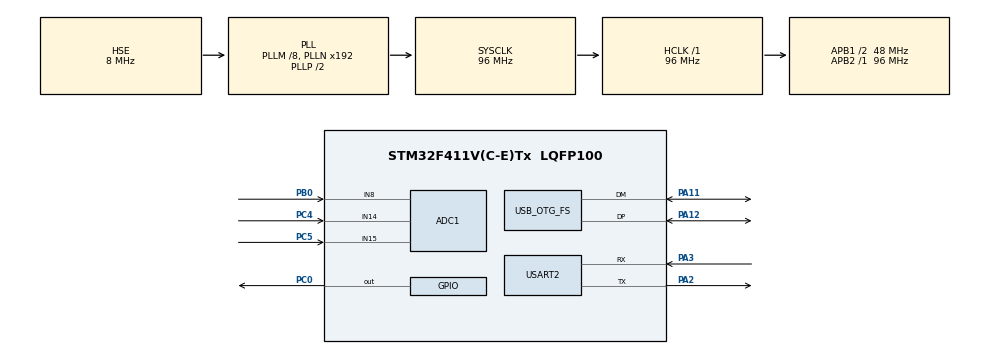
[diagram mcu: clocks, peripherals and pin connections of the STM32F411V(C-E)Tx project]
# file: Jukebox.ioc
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ADC1.Channel-0\#ChannelRegularConversion=ADC_CHANNEL_14
ADC1.Channel-1\#ChannelRegularConversion=ADC_CHANNEL_15
ADC1.Channel-2\#ChannelRegularConversion=ADC_CHANNEL_8
ADC1.ContinuousConvMode=DISABLE
ADC1.DiscontinuousConvMode=ENABLE
ADC1.NbrOfConversion=3
ADC1.NbrOfConversionFlag=1
ADC1.Rank-0\#ChannelRegularConversion=1
ADC1.Rank-1\#ChannelRegularConversion=2
ADC1.Rank-2\#ChannelRegularConversion=3
ADC1.SamplingTime-0\#ChannelRegularConversion=ADC_SAMPLETIME_3CYCLES
ADC1.SamplingTime-1\#ChannelRegularConversion=ADC_SAMPLETIME_3CYCLES
ADC1.SamplingTime-2\#ChannelRegularConversion=ADC_SAMPLETIME_3CYCLES
ADC1.ScanConvMode=ENABLE
ADC1.master=1
Dma.ADC1.0.Direction=DMA_PERIPH_TO_MEMORY
Dma.ADC1.0.FIFOMode=DMA_FIFOMODE_DISABLE
Dma.ADC1.0.Instance=DMA2_Stream0
Dma.ADC1.0.MemDataAlignment=DMA_MDATAALIGN_HALFWORD
Dma.ADC1.0.MemInc=DMA_MINC_ENABLE
Dma.ADC1.0.Mode=DMA_NORMAL
Dma.ADC1.0.PeriphDataAlignment=DMA_PDATAALIGN_HALFWORD
Dma.ADC1.0.PeriphInc=DMA_PINC_DISABLE
Dma.ADC1.0.Priority=DMA_PRIORITY_LOW
Dma.Request0=ADC1
FATFS._FS_EXFAT=1
FATFS._USE_LFN=2
FREERTOS.HEAP_NUMBER=3
FREERTOS.Tasks01=defaultTask,24,128,StartDefaultTask,Default,NULL
Mcu.Family=STM32F4
Mcu.Name=STM32F411V(C-E)Tx
Mcu.Package=LQFP100
NVIC.ADC_IRQn=true\:5\:0\:false\:false\:true\:true\:true\:true
NVIC.DMA2_Stream0_IRQn=true\:5\:0\:false\:false\:true\:true\:false\:true
NVIC.OTG_FS_IRQn=true\:5\:0\:false\:false\:true\:true\:false\:true
NVIC.PriorityGroup=NVIC_PRIORITYGROUP_4
NVIC.TIM1_UP_TIM10_IRQn=true\:0\:0\:false\:false\:true\:false\:false\:true
NVIC.TimeBase=TIM1_UP_TIM10_IRQn
NVIC.TimeBaseIP=TIM1
NVIC.USART2_IRQn=true\:5\:0\:false\:false\:true\:true\:true\:true
PA11.Mode=Host_Only
PA11.Signal=USB_OTG_FS_DM
PA12.Mode=Host_Only
PA12.Signal=USB_OTG_FS_DP
PA2.Mode=Asynchronous
PA2.Signal=USART2_TX
PA3.Mode=Asynchronous
PA3.Signal=USART2_RX
PB0.Signal=ADCx_IN8
PC0.Signal=GPIO_Output
PC4.Signal=ADCx_IN14
PC5.Signal=ADCx_IN15
PH0\ -\ OSC_IN.Mode=HSE-External-Oscillator
PH0\ -\ OSC_IN.Signal=RCC_OSC_IN
PH1\ -\ OSC_OUT.Mode=HSE-External-Oscillator
PH1\ -\ OSC_OUT.Signal=RCC_OSC_OUT
ProjectManager.HeapSize=0x200
ProjectManager.StackSize=0x400
ProjectManager.TargetToolchain=STM32CubeIDE
RCC.48MHZClocksFreq_Value=48000000
RCC.AHBFreq_Value=96000000
RCC.APB1CLKDivider=RCC_HCLK_DIV2
RCC.APB1Freq_Value=48000000
RCC.APB1TimFreq_Value=96000000
RCC.APB2Freq_Value=96000000
RCC.APB2TimFreq_Value=96000000
RCC.CortexFreq_Value=96000000
RCC.HCLKFreq_Value=96000000
RCC.HSE_VALUE=8000000
RCC.HSI_VALUE=16000000
RCC.LSE_VALUE=32768
RCC.PLLM=8
RCC.SYSCLKFreq_VALUE=96000000
RCC.SYSCLKSource=RCC_SYSCLKSOURCE_PLLCLK
RCC.VCOOutputFreq_Value=192000000
SH.ADCx_IN14.0=ADC1_IN14,IN14
SH.ADCx_IN15.0=ADC1_IN15,IN15
SH.ADCx_IN8.0=ADC1_IN8,IN8
USART2.VirtualMode=VM_ASYNC
USB_HOST.BSP.number=1
USB_HOST.USBH_DEBUG_LEVEL=0
USB_HOST.USBH_HandleTypeDef=hUsbHostFS
USB_HOST.USBH_PROCESS_PRIO=osPriorityNormal
USB_HOST.USBH_PROCESS_STACK_SIZE=2048
USB_HOST.VirtualModeFS=Msc
USB_HOST0.BSP.STBoard=false
USB_HOST0.BSP.api=Unknown
USB_HOST0.BSP.i2caddr=0
USB_HOST0.BSP.instance=PC0
USB_HOST0.BSP.ip=GPIO
USB_HOST0.BSP.mode=Output
USB_HOST0.BSP.name=Drive_VBUS_FS
USB_HOST0.BSP.solution=PC0
USB_OTG_FS.VirtualMode=Host_Only
USB_OTG_FS.phy_itface=HCD_PHY_EMBEDDED
VP_CRC_VS_CRC.Mode=CRC_Activate
VP_FATFS_VS_USB.Mode=USB
VP_FREERTOS_VS_CMSIS_V2.Mode=CMSIS_V2
VP_SYS_VS_tim1.Mode=TIM1
VP_USB_HOST_VS_USB_HOST_MSC_FS.Mode=MSC_FS
board=STM32F411E-DISCO

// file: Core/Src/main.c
/* USER CODE BEGIN Header */
/**
  ******************************************************************************
  * @file           : main.c
  * @brief          : Main program body
  ******************************************************************************
  * @attention
  *
  * <h2><center>&copy; Copyright (c) 2019 STMicroelectronics.
  * All rights reserved.</center></h2>
  *
  * This software component is licensed by ST under Ultimate Liberty license
  * SLA0044, the "License"; You may not use this file except in compliance with
  * the License. You may obtain a copy of the License at:
  *                             www.st.com/SLA0044
  *
  ******************************************************************************
  */
/* USER CODE END Header */

#include "main.h"
#include "cmsis_os.h"
#include "adc.h"
#include "crc.h"
#include "dma.h"
#include "fatfs.h"
#include "usart.h"
#include "usb_host.h"
#include "gpio.h"

/* USER CODE BEGIN Includes */
#include "JukeboxStart.h"
/* USER CODE END Includes */

void SystemClock_Config(void);
void MX_FREERTOS_Init(void);

int main(void)
{

  /* MCU Configuration--------------------------------------------------------*/

  /* Reset of all peripherals, Initializes the Flash interface and the Systick. */
  HAL_Init();

  /* Configure the system clock */
  SystemClock_Config();

  /* Initialize all configured peripherals */
  MX_GPIO_Init();
  MX_DMA_Init();
  MX_ADC1_Init();
  MX_CRC_Init();
  MX_USART2_UART_Init();
  /* USER CODE BEGIN 2 */
  JukeboxStart();
  /* USER CODE END 2 */

  /* Call init function for freertos objects (in freertos.c) */
  MX_FREERTOS_Init();

  /* Start scheduler */
  osKernelStart();

  /* We should never get here as control is now taken by the scheduler */

  /* Infinite loop */
  while (1)
  {

  }
}

void SystemClock_Config(void)
{
  RCC_OscInitTypeDef RCC_OscInitStruct = {0};
  RCC_ClkInitTypeDef RCC_ClkInitStruct = {0};

  /** Configure the main internal regulator output voltage
  */
  __HAL_RCC_PWR_CLK_ENABLE();
  __HAL_PWR_VOLTAGESCALING_CONFIG(PWR_REGULATOR_VOLTAGE_SCALE1);
  /** Initializes the CPU, AHB and APB busses clocks
  */
  RCC_OscInitStruct.OscillatorType = RCC_OSCILLATORTYPE_HSE;
  RCC_OscInitStruct.HSEState = RCC_HSE_ON;
  RCC_OscInitStruct.PLL.PLLState = RCC_PLL_ON;
  RCC_OscInitStruct.PLL.PLLSource = RCC_PLLSOURCE_HSE;
  RCC_OscInitStruct.PLL.PLLM = 8;
  RCC_OscInitStruct.PLL.PLLN = 192;
  RCC_OscInitStruct.PLL.PLLP = RCC_PLLP_DIV2;
  RCC_OscInitStruct.PLL.PLLQ = 4;
  if (HAL_RCC_OscConfig(&RCC_OscInitStruct) != HAL_OK)
  {
    Error_Handler();
  }
  /** Initializes the CPU, AHB and APB busses clocks
  */
  RCC_ClkInitStruct.ClockType = RCC_CLOCKTYPE_HCLK|RCC_CLOCKTYPE_SYSCLK
                              |RCC_CLOCKTYPE_PCLK1|RCC_CLOCKTYPE_PCLK2;
  RCC_ClkInitStruct.SYSCLKSource = RCC_SYSCLKSOURCE_PLLCLK;
  RCC_ClkInitStruct.AHBCLKDivider = RCC_SYSCLK_DIV1;
  RCC_ClkInitStruct.APB1CLKDivider = RCC_HCLK_DIV2;
  RCC_ClkInitStruct.APB2CLKDivider = RCC_HCLK_DIV1;

  if (HAL_RCC_ClockConfig(&RCC_ClkInitStruct, FLASH_LATENCY_3) != HAL_OK)
  {
    Error_Handler();
  }
}

void HAL_TIM_PeriodElapsedCallback(TIM_HandleTypeDef *htim)
{
  if (htim->Instance == TIM1) {
    HAL_IncTick();
  }
}

/************************ (C) COPYRIGHT STMicroelectronics *****END OF FILE****/

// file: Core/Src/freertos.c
/* USER CODE BEGIN Header */
/**
  ******************************************************************************
  * File Name          : freertos.c
  * Description        : Code for freertos applications
  ******************************************************************************
  * @attention
  *
  * <h2><center>&copy; Copyright (c) 2019 STMicroelectronics.
  * All rights reserved.</center></h2>
  *
  * This software component is licensed by ST under Ultimate Liberty license
  * SLA0044, the "License"; You may not use this file except in compliance with
  * the License. You may obtain a copy of the License at:
  *                             www.st.com/SLA0044
  *
  ******************************************************************************
  */
/* USER CODE END Header */

#include "FreeRTOS.h"
#include "task.h"
#include "main.h"
#include "cmsis_os.h"

osThreadId_t defaultTaskHandle;

void StartDefaultTask(void *argument); // for v2

extern void MX_FATFS_Init(void);
extern void MX_USB_HOST_Init(void);
void MX_FREERTOS_Init(void); /* (MISRA C 2004 rule 8.1) */

void MX_FREERTOS_Init(void) {
osKernelInitialize(); // Initialize CMSIS-RTOS

  /* Create the thread(s) */
  /* definition and creation of defaultTask */
  const osThreadAttr_t defaultTask_attributes = {
    .name = "defaultTask",
    .priority = (osPriority_t) osPriorityNormal,
    .stack_size = 128
  };
  defaultTaskHandle = osThreadNew(StartDefaultTask, NULL, &defaultTask_attributes);

}

void StartDefaultTask(void *argument)
{
  /* init code for FATFS */
  MX_FATFS_Init();

  /* init code for USB_HOST */
  MX_USB_HOST_Init();

  for(;;)
  {
    osDelay(1);
  }
}

/************************ (C) COPYRIGHT STMicroelectronics *****END OF FILE****/
